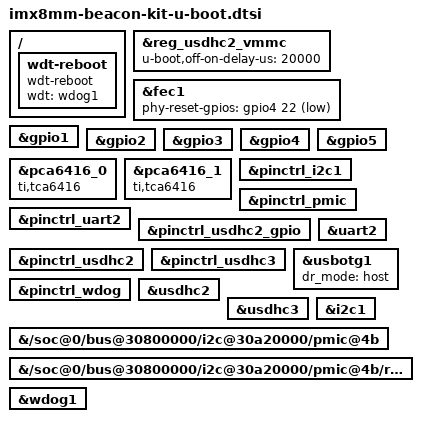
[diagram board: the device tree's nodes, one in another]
// SPDX-License-Identifier: GPL-2.0+
/*
 * Copyright 2020 Compass Electronics Group, LLC
 */

#include "imx8mm-u-boot.dtsi"

/ {
	wdt-reboot {
		compatible = "wdt-reboot";
		wdt = <&wdog1>;
		u-boot,dm-spl;
	};
};

&reg_usdhc2_vmmc {
	u-boot,off-on-delay-us = <20000>;
};

&fec1 {
	phy-reset-gpios = <&gpio4 22 GPIO_ACTIVE_LOW>;
};

&gpio1 {
	u-boot,dm-spl;
};

&gpio2 {
	u-boot,dm-spl;
};

&gpio3 {
	u-boot,dm-spl;
};

&gpio4 {
	u-boot,dm-spl;
};

&gpio5 {
	u-boot,dm-spl;
};

&pca6416_0 {
	compatible = "ti,tca6416";
};

&pca6416_1 {
	compatible = "ti,tca6416";
};

&pinctrl_i2c1 {
	u-boot,dm-spl;
};

&pinctrl_pmic {
	u-boot,dm-spl;
};

&pinctrl_uart2 {
	u-boot,dm-spl;
};

&pinctrl_usdhc2_gpio {
	u-boot,dm-spl;
};

&pinctrl_usdhc2 {
	u-boot,dm-spl;
};

&pinctrl_usdhc3 {
	u-boot,dm-spl;
};

&pinctrl_wdog {
	u-boot,dm-spl;
};

&uart2 {
	u-boot,dm-spl;
};

&usbotg1 {
	dr_mode="host";
};

&usdhc2 {
	u-boot,dm-spl;
};

&usdhc3 {
	u-boot,dm-spl;
};

&i2c1 {
	u-boot,dm-spl;
};

&{/soc@0/bus@30800000/i2c@30a20000/pmic@4b} {
	u-boot,dm-spl;
};

&{/soc@0/bus@30800000/i2c@30a20000/pmic@4b/regulators} {
	u-boot,dm-spl;
};

&wdog1 {
	u-boot,dm-spl;
};
